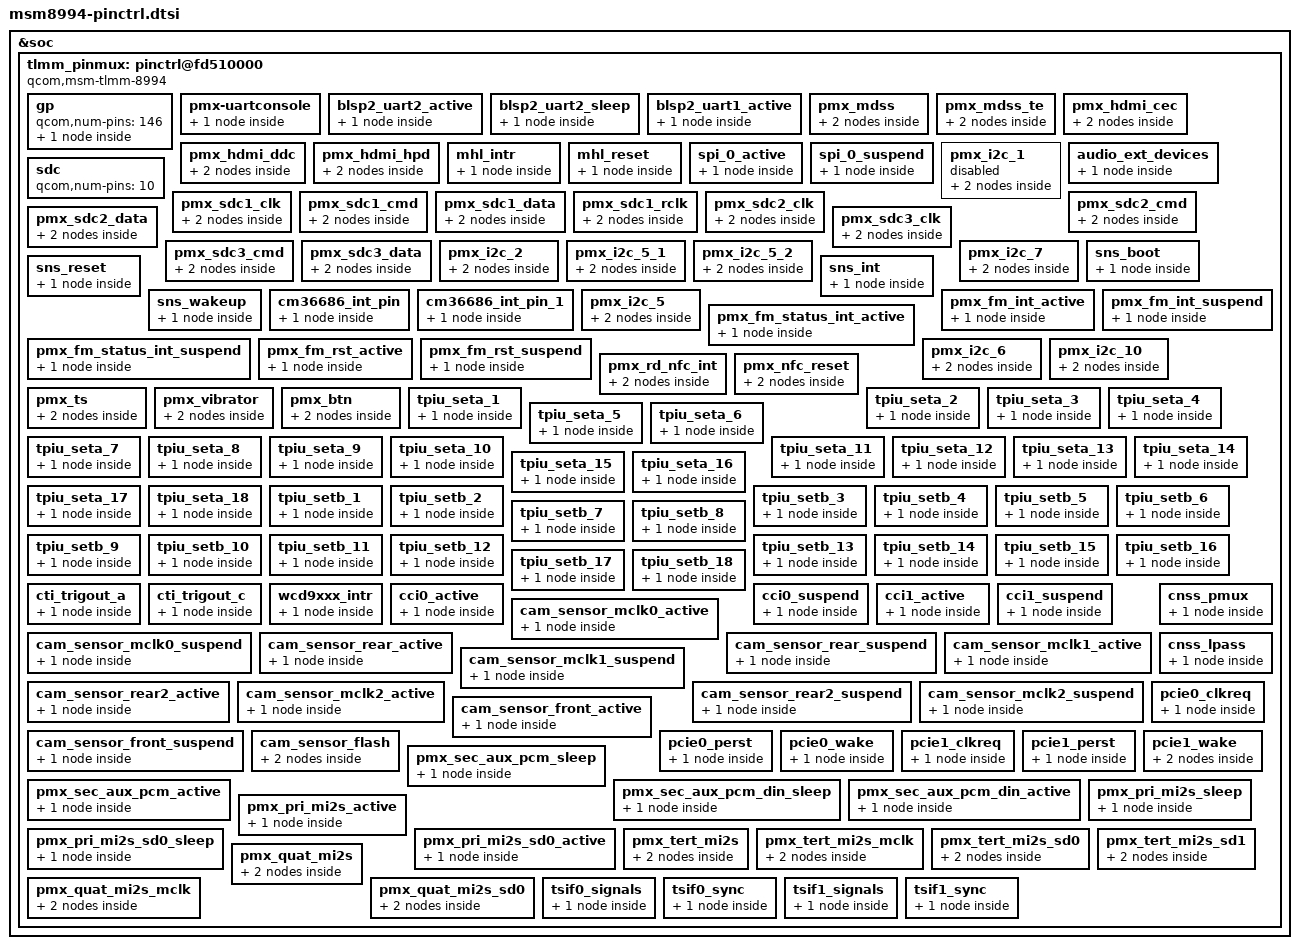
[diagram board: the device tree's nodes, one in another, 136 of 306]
/* Copyright (c) 2013-2015, The Linux Foundation. All rights reserved.
 * Copyright (C) 2016 XiaoMi, Inc.
 *
 * This program is free software; you can redistribute it and/or modify
 * it under the terms of the GNU General Public License version 2 and
 * only version 2 as published by the Free Software Foundation.
 *
 * This program is distributed in the hope that it will be useful,
 * but WITHOUT ANY WARRANTY; without even the implied warranty of
 * MERCHANTABILITY or FITNESS FOR A PARTICULAR PURPOSE.  See the
 * GNU General Public License for more details.
 */

&soc {
	tlmm_pinmux: pinctrl@fd510000 {
		compatible = "qcom,msm-tlmm-8994", "qcom,msm-tlmm-8974";
		reg = <0xfd510000 0x4000>;
		interrupts = <0 208 0>;

		/*General purpose pins*/
		gp: gp {
			qcom,num-pins = <146>;
			#qcom,pin-cells = <1>;

			msm_gpio: msm_gpio {
				compatible = "qcom,msm-tlmm-gp";
				gpio-controller;
				#gpio-cells = <2>;
				interrupt-controller;
				#interrupt-cells = <2>;
				qcom,direct-connect-irqs = <8>;
				num_irqs = <146>;
			};
		};

		pmx-uartconsole {
			qcom,pins = <&gp 4>, <&gp 5>;
			qcom,num-grp-pins = <2>;
			qcom,pin-func = <2>;
			label = "uart-console";

		uart_console_sleep: uart-console {
				drive-strength = <2>;
				bias-pull-down;
			};
		};

		blsp2_uart2_active {
			qcom,pins = <&gp 45>, <&gp 46>, <&gp 47>, <&gp 48>;
			qcom,num-grp-pins = <4>;
			qcom,pin-func = <2>;
		        label = "blsp2_uart2_active";
			hsuart_active: default {
				drive-strength = <16>;
				bias-disable;
			};
		};

		blsp2_uart2_sleep {
			qcom,pins = <&gp 45>, <&gp 46>, <&gp 47>, <&gp 48>;
			qcom,num-grp-pins = <4>;
			qcom,pin-func = <0>;
		        label = "blsp2_uart2_sleep";
			hsuart_sleep: sleep {
				drive-strength = <2>;
				bias-disable;
			};
		};
		blsp2_uart1_active {
			qcom,pins = <&gp 41>, <&gp 42>;
			qcom,num-grp-pins = <2>;
			qcom,pin-func = <2>;
			label = "blsp2_uart1_active";
			uart1_default: uart1_default {
			drive-strength = <2>;
				bias-disable;
			};
		};

		pmx_mdss: pmx_mdss {
			label = "mdss-pins";
			qcom,pin-func = <0>;
			mdss_dsi_active: active {
				drive-strength = <8>; /* 8 mA */
				bias-disable = <0>; /* no pull */
			};
			mdss_dsi_suspend: suspend {
				drive-strength = <2>; /* 2 mA */
				bias-pull-down; /* pull down */
			};
		};

		pmx_mdss_te: pmx_mdss_te {
			label = "mdss-te-pins";
			qcom,pin-func = <1>;
			mdss_te_active: active {
				drive-strength = <2>; /* 8 mA */
				bias-pull-down = <0>; /* pull down*/
				input-debounce = <0>;
			};
			mdss_te_suspend: suspend {
				drive-strength = <2>; /* 2 mA */
				bias-pull-down; /* pull down */
				input-debounce = <0>;
			};
		};

		pmx_hdmi_cec: pmx_hdmi_cec {
			qcom,pin-func = <1>;
			label = "hdmi-cec-pins";
			mdss_hdmi_cec_active: cec_active {
				drive-strength = <2>;
				bias-pull-up;
			};
			mdss_hdmi_cec_suspend: cec_suspend {
				drive-strength = <2>;
				bias-pull-down;
			};
		};

		pmx_hdmi_ddc: pmx_hdmi_ddc {
			qcom,pin-func = <1>;
			label = "hdmi-ddc-pins";
			mdss_hdmi_ddc_active: ddc_active {
				drive-strength = <2>;
				bias-pull-up;
			};
			mdss_hdmi_ddc_suspend: ddc_suspend {
				drive-strength = <2>;
				bias-pull-down;
			};
		};

		pmx_hdmi_hpd: pmx_hdmi_hpd {
			qcom,pin-func = <1>;
			label = "hdmi-hpd-pin";
			mdss_hdmi_hpd_active: hpd_active {
				drive-strength = <16>;
				bias-pull-down;
			};
			mdss_hdmi_hpd_suspend: hpd_suspend {
				drive-strength = <2>;
				bias-pull-down;
			};
		};

		mhl_intr: mhl_intr {
			qcom,pins = <&gp 57>;
			qcom,num-grp-pins = <1>;
			qcom,pin-func = <0>;
			label = "mhl_intr";

			mhl_intr_active: mhl_intr_active {
				bias-pull-up;
				input-enable;
			};
		};

		mhl_reset: mhl_reset {
			qcom,pins = <&gp 58>;
			qcom,num-grp-pins = <1>;
			qcom,pin-func = <0>;
			label = "mhl_reset";

			mhl_reset_active: mhl_reset_active {
				drive-strength = <2>;
				bias-pull-down;
				output-low;
			};
		};

		spi_0_active {
			/* MOSI, MISO, CLK */
			qcom,pins = <&gp 0>, <&gp 1>, <&gp 3>;
			qcom,num-grp-pins = <3>;
			qcom,pin-func = <1>;
			label = "spi_0-active";

			spi_0_active: spi_active {
			       drive-strength = <12>;
			       bias-disable = <0>;
		        };
		};

		spi_0_suspend {
			/* MOSI, MISO, CLK */
			qcom,pins = <&gp 0>, <&gp 1>, <&gp 3>;
			qcom,num-grp-pins = <3>;
			qcom,pin-func = <1>;
			label = "spi_0-suspend";

			spi_0_sleep: spi_sleep {
			       drive-strength = <2>;
			       bias-pull-down;
		        };
		};

		pmx_i2c_1 {
			qcom,pins = <&gp 2>, <&gp 3>; /* SDA, SCL */
			qcom,num-grp-pins = <2>;
			qcom,pin-func = <3>;
			label = "pmx_i2c_1";

			status = "disabled";

			i2c_1_active: i2c_1_active {
				drive-strength = <2>;
				bias-disable;
			};

			i2c_1_sleep: i2c_1_sleep {
				drive-strength = <2>;
				bias-disable;
			};
		};

		audio_ext_devices {
			qcom,pins = <&gp 96>;
			qcom,num-grp-pins = <1>;
			label = "audio-ext-speakers";
			/* default state */
			audio_ext_speakers: audio_ext_speakers {
				drive-strength = <2>;
				bias-pull-up;
			};
		};

		/* SDC pin type */
		sdc: sdc {
			/*
			 * 0-3 for sdc1
			 * 4-6 for sdc2
			 * 7-9 for sdc3
			 */
			qcom,num-pins = <10>;
			/*
			 * Order of pins:
			 * SDC1: CLK -> 0, CMD -> 1, DATA -> 2, RCLK -> 3
			 * SDC2: CLK -> 4, CMD -> 5, DATA -> 6
			 * SDC3: CLK -> 7, CMD -> 8, DATA -> 9
			 */
			#qcom,pin-cells = <1>;
		};

		pmx_sdc1_clk {
			qcom,pins = <&sdc 0>;
			qcom,num-grp-pins = <1>;
			label = "sdc1-clk";
			sdc1_clk_on: clk_on {
				bias-disable; /* NO pull */
				drive-strength = <16>; /* 16 MA */
			};
			sdc1_clk_off: clk_off {
				bias-disable; /* NO pull */
				drive-strength = <2>; /* 2 MA */
			};
		};

		pmx_sdc1_cmd {
			qcom,pins = <&sdc 1>;
			qcom,num-grp-pins = <1>;
			label = "sdc1-cmd";
			sdc1_cmd_on: cmd_on {
				bias-pull-up; /* pull up */
				drive-strength = <8>; /* 8 MA */
			};
			sdc1_cmd_off: cmd_off {
				bias-pull-up = <0x3>; /* pull up */
				drive-strength = <2>; /* 2 MA */
			};
		};

		pmx_sdc1_data {
			qcom,pins = <&sdc 2>;
			qcom,num-grp-pins = <1>;
			label = "sdc1-data";
			sdc1_data_on: data_on {
				bias-pull-up; /* pull up */
				drive-strength = <8>; /* 8 MA */
			};
			sdc1_data_off: data_off {
				bias-pull-up; /* pull up */
				drive-strength = <2>; /* 2 MA */
			};
		};

		pmx_sdc1_rclk {
			qcom,pins = <&sdc 3>;
			qcom,num-grp-pins = <1>;
			label = "sdc1-rclk";
			sdc1_rclk_on: rclk_on {
				bias-pull-down; /* pull down */
			};
			sdc1_rclk_off: rclk_off {
				bias-pull-down; /* pull down */
			};
		};

		pmx_sdc2_clk {
			qcom,pins = <&sdc 4>;
			qcom,num-grp-pins = <1>;
			label = "sdc2-clk";
			sdc2_clk_on: clk_on {
				bias-disable; /* NO pull */
				drive-strength = <16>; /* 16 MA */
			};
			sdc2_clk_off: clk_off {
				bias-disable; /* NO pull */
				drive-strength = <2>; /* 2 MA */
			};
		};

		pmx_sdc2_cmd {
			qcom,pins = <&sdc 5>;
			qcom,num-grp-pins = <1>;
			label = "sdc2-cmd";
			sdc2_cmd_on: cmd_on {
				bias-pull-up; /* pull up */
				drive-strength = <10>; /* 10 MA */
			};
			sdc2_cmd_off: cmd_off {
				bias-pull-up; /* pull up */
				drive-strength = <2>; /* 2 MA */
			};
		};

		pmx_sdc2_data {
			qcom,pins = <&sdc 6>;
			qcom,num-grp-pins = <1>;
			label = "sdc2-data";
			sdc2_data_on: data_on {
				bias-pull-up; /* pull up */
				drive-strength = <10>; /* 10 MA */
			};
			sdc2_data_off: data_off {
				bias-pull-up; /* pull up */
				drive-strength = <2>; /* 2 MA */
			};
		};

		pmx_sdc3_clk {
			qcom,pins = <&sdc 7>;
			qcom,num-grp-pins = <1>;
			label = "sdc3-clk";
			sdc3_clk_on: clk_on {
				bias-disable; /* NO pull */
				drive-strength = <16>; /* 16 MA */
			};
			sdc3_clk_off: clk_off {
				bias-disable; /* NO pull */
				drive-strength = <2>; /* 2 MA */
			};
		};

		pmx_sdc3_cmd {
			qcom,pins = <&sdc 8>;
			qcom,num-grp-pins = <1>;
			label = "sdc3-cmd";
			sdc3_cmd_on: cmd_on {
				bias-pull-up; /* pull up */
				drive-strength = <10>; /* 10 MA */
			};
			sdc3_cmd_off: cmd_off {
				bias-pull-up; /* pull up */
				drive-strength = <2>; /* 2 MA */
			};
		};

		pmx_sdc3_data {
			qcom,pins = <&sdc 9>;
			qcom,num-grp-pins = <1>;
			label = "sdc3-data";
			sdc3_data_on: data_on {
				bias-pull-up; /* pull up */
				drive-strength = <10>; /* 10 MA */
			};
			sdc3_data_off: data_off {
				bias-pull-up; /* pull up */
				drive-strength = <2>; /* 2 MA */
			};
		};

		pmx_i2c_2 {
			qcom,pins = <&gp 6>, <&gp 7>; /* SDA, SCL */
			qcom,num-grp-pins = <2>;
			qcom,pin-func = <3>;
			label = "pmx_i2c_2";

			i2c_2_active: i2c_2_active {
				drive-strength = <2>;
				bias-disable;
			};

			i2c_2_sleep: i2c_2_sleep {
				drive-strength = <2>;
				bias-disable;
			};
		};

		pmx_i2c_5_1 {
			qcom,pins = <&gp 23>; /* SDA*/
			qcom,num-grp-pins = <1>;
			qcom,pin-func = <4>;
			label = "pmx_i2c_5_1";

			i2c_5_1_active: i2c_5_1_active {
				drive-strength = <2>;
				bias-disable;
			};

			i2c_5_1_sleep: i2c_5_1_sleep {
				drive-strength = <2>;
				bias-disable;
			};
		};

		pmx_i2c_5_2 {
			qcom,pins = <&gp 24>; /* SCL*/
			qcom,num-grp-pins = <1>;
			qcom,pin-func = <5>;
			label = "pmx_i2c_5_2";

			i2c_5_2_active: i2c_5_2_active {
				drive-strength = <2>;
				bias-disable;
			};

			i2c_5_2_sleep: i2c_5_2_sleep {
				drive-strength = <2>;
				bias-disable;
			};
		};

		pmx_i2c_7 {
			qcom,pins = <&gp 43>, <&gp 44>; /* SDA, SCL */
			qcom,num-grp-pins = <2>;
			qcom,pin-func = <3>;
			label = "pmx_i2c_7";

			i2c_7_active: i2c_7_active {
			drive-strength = <2>;
			bias-disable;
			};

			i2c_7_sleep: i2c_7_sleep {
				drive-strength = <2>;
				bias-disable;
			};
		};

		sns_boot: sns_boot {
			qcom,pins = <&gp 40>;
			qcom,num-grp-pins = <1>;
			qcom,pin-func = <0>;
			label = "sns_boot";

			sns_boot_default: sns_boot_default {
				bias-disable;
				output-high;
				drive-strength = <2>;
			};

		};

		sns_reset: sns_reset {
			qcom,pins = <&gp 31>;
			qcom,num-grp-pins = <1>;
			qcom,pin-func = <0>;
			label = "sns_reset";

			sns_reset_default: sns_reset_default {
				bias-disable;
				output-high;
				drive-strength = <2>;
			};
		};

		sns_int: sns_int {
			qcom,pins = <&gp 1>;
			qcom,num-grp-pins = <1>;
			qcom,pin-func = <0>;
			label = "sns_int";

			sns_int_default: sns_int_default {
				bias-pull-up;
				input-enable;
				drive-strength = <2>;
			};
		};

		sns_wakeup: sns_wakeup {
			qcom,pins = <&gp 39>;
			qcom,num-grp-pins = <1>;
			qcom,pin-func = <0>;
			label = "sns_wakeup";

			sns_wakeup_default: sns_wakeup_default {
				bias-disable;
				output-low;
				drive-strength = <2>;
			};
		};

		cm36686_int_pin {
			qcom,pins = <&gp 90>;
			qcom,num-grp-pins = <1>;
			qcom,pin-func = <0>;
			label = "cm36686-irq";
			cm36686_int_default: cm36686_int_default {
				bias-pull-up;
				input-enable;
				drive-strength = <2>;
			};
		};

		cm36686_int_pin_1 {
			qcom,pins = <&gp 102>;
			qcom,num-grp-pins = <1>;
			qcom,pin-func = <0>;
			label = "cm36686-irq_1";
			cm36686_int_default_1: cm36686_int_default_1 {
				bias-pull-up;
				input-enable;
				drive-strength = <2>;
			};
		};


		pmx_i2c_5 {
			qcom,pins = <&gp 83>, <&gp 84>; /* SDA, SCL */
			qcom,num-grp-pins = <2>;
			qcom,pin-func = <3>;
			label = "pmx_i2c_5";

			i2c_5_active: i2c_5_active {
				drive-strength = <2>;
				bias-disable;
			};

			i2c_5_sleep: i2c_5_sleep {
				drive-strength = <2>;
				bias-disable;
			};
		};

		pmx_fm_int_active {
			qcom,pins = <&gp 9>;
			qcom,pin-func = <0>;
			qcom,num-grp-pins = <1>;
			label = "pmx_fm_int_active";

			fm_int_active: fm_int_active {
				drive-strength = <16>;
				bias-pull-up;
			};
		};

		pmx_fm_int_suspend {
			qcom,pins = <&gp 9>;
			qcom,pin-func = <0>;
			qcom,num-grp-pins = <1>;
			label = "pmx_fm_int_suspend";

			fm_int_suspend: fm_int_suspend {
				drive-strength = <16>;
				bias-pull-up;
			};
		};

		pmx_fm_status_int_active {
			qcom,pins = <&gp 11>;
			qcom,pin-func = <0>;
			qcom,num-grp-pins = <1>;
			label = "pmx_fm_status_int_active";

			fm_status_int_active: fm_status_int_active {
				drive-strength = <16>;
				bias-pull-up;
			};
		};

		pmx_fm_status_int_suspend {
			qcom,pins = <&gp 11>;
			qcom,pin-func = <0>;
			qcom,num-grp-pins = <1>;
			label = "pmx_fm_status_int_suspend";

			fm_status_int_suspend: fm_status_int_suspend {
				drive-strength = <16>;
				bias-pull-up;
			};
		};

		pmx_fm_rst_active {
			qcom,pins = <&gp 62>;
			qcom,pin-func = <0>;
			qcom,num-grp-pins = <1>;
			label = "pmx_fm_rst_active";

			fm_rst_active: fm_rst_active {
				drive-strength = <16>;
				bias-pull-down;
			};
		};

		pmx_fm_rst_suspend {
			qcom,pins = <&gp 62>;
			qcom,pin-func = <0>;
			qcom,num-grp-pins = <1>;
			label = "pmx_fm_rst_suspend";

			fm_rst_suspend: fm_rst_suspend {
				drive-strength = <16>;
				bias-pull-down;
			};
		};

		pmx_i2c_6 {
			qcom,pins = <&gp 28>, <&gp 27>; /* SDA, SCL */
			qcom,num-grp-pins = <2>;
			qcom,pin-func = <3>;
			label = "pmx_i2c_6";

			i2c_6_active: i2c_6_active {
				drive-strength = <2>;
				bias-disable;
			};

			i2c_6_sleep: i2c_6_sleep {
				drive-strength = <2>;
				bias-disable;
			};
		};

		pmx_i2c_10 {
			qcom,pins = <&gp 55>, <&gp 56>; /* SDA, SCL */
			qcom,num-grp-pins = <2>;
			qcom,pin-func = <4>;
			label = "pmx_i2c_10";

			i2c_10_active: i2c_10_active {
				drive-strength = <2>;
				bias-disable;
			};

			i2c_10_sleep: i2c_10_sleep {
				drive-strength = <2>;
				bias-disable;
			};
		};

		pmx_rd_nfc_int{
			qcom,pins = <&gp 29>;
			qcom,pin-func = <0>;
			qcom,num-grp-pins = <1>;
			label = "pmx_nfc_int";

			nfc_int_active: active {
				drive-strength = <6>;
				bias-pull-up;
			};

			nfc_int_suspend: suspend {
				drive-strength = <6>;
				bias-pull-up;
			};
		};

		pmx_nfc_reset{
			qcom,pins = <&gp 30>;
			qcom,pin-func = <0>;
			qcom,num-grp-pins = <1>;
			label = "pmx_nfc_disable";

			nfc_disable_active: active {
				drive-strength = <6>;
				bias-pull-up;
			};

			nfc_disable_suspend: suspend {
				drive-strength = <6>;
				bias-disable;
			};
		};

		pmx_ts {
			qcom,pins = <&gp 63>, <&gp 61>;
			qcom,pin-func = <0>;
			qcom,num-grp-pins = <2>;
			label = "pmx_ts";

			ts_active: ts_active {
				drive-strength = <8>;
				bias-pull-up;
			};

			ts_suspend: ts_suspend {
				drive-strength = <8>;
				bias-disable;
			};
		};

		pmx_vibrator {
			qcom,pins = <&gp 21>;
			qcom,pin-func = <0>;
			qcom,num-grp-pins = <1>;
			label = "pmx_vibrator";

			vibrator_active: vibrator_active {
				drive-strength = <8>;
				bias-pull-up;
			};

			vibrator_suspend: vibrator_suspend {
				drive-strength = <8>;
				bias-disable;
			};
		};

		pmx_btn {
			qcom,pins = <&gp 114>;
			qcom,pin-func = <0>;
			qcom,num-grp-pins = <1>;
			label = "pmx_btn";

			btn_active: btn_active {
				drive-strength = <8>;
				bias-pull-up;
			};

			btn_suspend: btn_suspend {
				drive-strength = <8>;
				bias-disable;
			};
		};

		/* CoreSight */
		tpiu_seta_1 {
			qcom,pins = <&gp 27>;
			qcom,num-grp-pins = <1>;
			qcom,pin-func = <5>;
			label = "tpiu-seta-1";
			seta_1: seta {
				drive-strength = <16>;
				bias-disable;
			};
		};

		tpiu_seta_2 {
			qcom,pins = <&gp 28>;
			qcom,num-grp-pins = <1>;
			qcom,pin-func = <4>;
			label = "tpiu-seta-2";
			seta_2: seta {
				drive-strength = <16>;
				bias-disable;
			};
		};

		tpiu_seta_3 {
			qcom,pins = <&gp 53>;
			qcom,num-grp-pins = <1>;
			qcom,pin-func = <10>;
			label = "tpiu-seta-3";
			seta_3: seta {
				drive-strength = <16>;
				bias-disable;
			};
		};

		tpiu_seta_4 {
			qcom,pins = <&gp 54>;
			qcom,num-grp-pins = <1>;
			qcom,pin-func = <11>;
			label = "tpiu-seta-4";
			seta_4: seta {
				drive-strength = <16>;
				bias-disable;
			};
		};

		tpiu_seta_5 {
			//qcom,pins = <&gp 63>;
			qcom,num-grp-pins = <1>;
			qcom,pin-func = <9>;
			label = "tpiu-seta-5";
			seta_5: seta {
				drive-strength = <16>;
				bias-disable;
			};
		};

		tpiu_seta_6 {
			qcom,pins = <&gp 64>;
			qcom,num-grp-pins = <1>;
			qcom,pin-func = <7>;
			label = "tpiu-seta-6";
			seta_6: seta {
				drive-strength = <16>;
				bias-disable;
			};
		};

		tpiu_seta_7 {
			qcom,pins = <&gp 65>;
			qcom,num-grp-pins = <1>;
			qcom,pin-func = <7>;
			label = "tpiu-seta-7";
			seta_7: seta {
				drive-strength = <16>;
				bias-disable;
			};
		};

		tpiu_seta_8 {
			qcom,pins = <&gp 66>;
			qcom,num-grp-pins = <1>;
			qcom,pin-func = <8>;
			label = "tpiu-seta-8";
			seta_8: seta {
				drive-strength = <16>;
				bias-disable;
			};
		};

		tpiu_seta_9 {
			qcom,pins = <&gp 67>;
			qcom,num-grp-pins = <1>;
			qcom,pin-func = <8>;
			label = "tpiu-seta-9";
			seta_9: seta {
				drive-strength = <16>;
				bias-disable;
			};
		};

		tpiu_seta_10 {
			qcom,pins = <&gp 74>;
			qcom,num-grp-pins = <1>;
			qcom,pin-func = <8>;
			label = "tpiu-seta-10";
			seta_10: seta {
				drive-strength = <16>;
				bias-disable;
			};
		};

		tpiu_seta_11 {
			qcom,pins = <&gp 75>;
			qcom,num-grp-pins = <1>;
			qcom,pin-func = <6>;
			label = "tpiu-seta-11";
			seta_11: seta {
				drive-strength = <16>;
				bias-disable;
			};
		};

		tpiu_seta_12 {
			qcom,pins = <&gp 76>;
			qcom,num-grp-pins = <1>;
			qcom,pin-func = <6>;
			label = "tpiu-seta-12";
			seta_12: seta {
				drive-strength = <16>;
				bias-disable;
			};
		};

		tpiu_seta_13 {
			qcom,pins = <&gp 77>;
			qcom,num-grp-pins = <1>;
			qcom,pin-func = <6>;
			label = "tpiu-seta-13";
			seta_13: seta {
				drive-strength = <16>;
				bias-disable;
			};
		};

		tpiu_seta_14 {
			qcom,pins = <&gp 85>;
			qcom,num-grp-pins = <1>;
			qcom,pin-func = <6>;
			label = "tpiu-seta-14";
			seta_14: seta {
				drive-strength = <16>;
				bias-disable;
			};
		};

		tpiu_seta_15 {
			qcom,pins = <&gp 86>;
			qcom,num-grp-pins = <1>;
			qcom,pin-func = <6>;
			label = "tpiu-seta-15";
			seta_15: seta {
				drive-strength = <16>;
				bias-disable;
			};
		};

		tpiu_seta_16 {
			qcom,pins = <&gp 87>;
			qcom,num-grp-pins = <1>;
			qcom,pin-func = <5>;
			label = "tpiu-seta-16";
			seta_16: seta {
				drive-strength = <16>;
				bias-disable;
			};
		};

		tpiu_seta_17 {
			qcom,pins = <&gp 89>;
			qcom,num-grp-pins = <1>;
			qcom,pin-func = <3>;
			label = "tpiu-seta-17";
			seta_17: seta {
				drive-strength = <16>;
				bias-disable;
			};
		};

		tpiu_seta_18 {
			qcom,pins = <&gp 90>;
			qcom,num-grp-pins = <1>;
			qcom,pin-func = <3>;
			label = "tpiu-seta-18";
			seta_18: seta {
				drive-strength = <16>;
				bias-disable;
			};
		};

		tpiu_setb_1 {
			qcom,pins = <&gp 13>;
			qcom,num-grp-pins = <1>;
			qcom,pin-func = <4>;
			label = "tpiu-setb-1";
			setb_1: setb {
				drive-strength = <16>;
				bias-disable;
			};
		};

		tpiu_setb_2 {
			qcom,pins = <&gp 14>;
			qcom,num-grp-pins = <1>;
			qcom,pin-func = <4>;
			label = "tpiu-setb-2";
			setb_2: setb {
				drive-strength = <16>;
				bias-disable;
			};
		};

		tpiu_setb_3 {
			qcom,pins = <&gp 15>;
			qcom,num-grp-pins = <1>;
			qcom,pin-func = <3>;
			label = "tpiu-setb-3";
			setb_3: setb {
				drive-strength = <16>;
				bias-disable;
			};
		};

		tpiu_setb_4 {
			qcom,pins = <&gp 16>;
			qcom,num-grp-pins = <1>;
			qcom,pin-func = <3>;
			label = "tpiu-setb-4";
			setb_4: setb {
				drive-strength = <16>;
				bias-disable;
			};
		};

		tpiu_setb_5 {
			qcom,pins = <&gp 17>;
			qcom,num-grp-pins = <1>;
			qcom,pin-func = <6>;
			label = "tpiu-setb-5";
			setb_5: setb {
				drive-strength = <16>;
				bias-disable;
			};
		};

		tpiu_setb_6 {
			qcom,pins = <&gp 18>;
			qcom,num-grp-pins = <1>;
			qcom,pin-func = <6>;
			label = "tpiu-setb-6";
			setb_6: setb {
				drive-strength = <16>;
				bias-disable;
			};
		};

		tpiu_setb_7 {
			qcom,pins = <&gp 19>;
			qcom,num-grp-pins = <1>;
			qcom,pin-func = <6>;
			label = "tpiu-setb-7";
			setb_7: setb {
				drive-strength = <16>;
				bias-disable;
			};
		};

		tpiu_setb_8 {
			qcom,pins = <&gp 21>;
			qcom,num-grp-pins = <1>;
			qcom,pin-func = <6>;
			label = "tpiu-setb-8";
			setb_8: setb {
				drive-strength = <16>;
				bias-disable;
			};
		};

		tpiu_setb_9 {
			qcom,pins = <&gp 22>;
			qcom,num-grp-pins = <1>;
			qcom,pin-func = <6>;
			label = "tpiu-setb-9";
			setb_9: setb {
				drive-strength = <16>;
				bias-disable;
			};
		};

		tpiu_setb_10 {
			qcom,pins = <&gp 23>;
			qcom,num-grp-pins = <1>;
			qcom,pin-func = <7>;
			label = "tpiu-setb-10";
			setb_10: setb {
				drive-strength = <16>;
				bias-disable;
			};
		};

		tpiu_setb_11 {
			qcom,pins = <&gp 25>;
			qcom,num-grp-pins = <1>;
			qcom,pin-func = <8>;
			label = "tpiu-setb-11";
			setb_11: setb {
				drive-strength = <16>;
				bias-disable;
			};
		};

		tpiu_setb_12 {
			qcom,pins = <&gp 26>;
			qcom,num-grp-pins = <1>;
			qcom,pin-func = <7>;
			label = "tpiu-setb-12";
			setb_12: setb {
				drive-strength = <16>;
				bias-disable;
			};
		};

		tpiu_setb_13 {
			qcom,pins = <&gp 57>;
			qcom,num-grp-pins = <1>;
			qcom,pin-func = <7>;
			label = "tpiu-setb-13";
			setb_13: setb {
				drive-strength = <16>;
				bias-disable;
			};
		};

		tpiu_setb_14 {
			qcom,pins = <&gp 58>;
			qcom,num-grp-pins = <1>;
			qcom,pin-func = <7>;
			label = "tpiu-setb-14";
			setb_14: setb {
				drive-strength = <16>;
				bias-disable;
			};
		};

		tpiu_setb_15 {
			qcom,pins = <&gp 91>;
			qcom,num-grp-pins = <1>;
			qcom,pin-func = <7>;
			label = "tpiu-setb-15";
			setb_15: setb {
				drive-strength = <16>;
				bias-disable;
			};
		};

		tpiu_setb_16 {
			qcom,pins = <&gp 92>;
			qcom,num-grp-pins = <1>;
			qcom,pin-func = <5>;
			label = "tpiu-setb-16";
			setb_16: setb {
				drive-strength = <16>;
				bias-disable;
			};
		};

		tpiu_setb_17 {
			qcom,pins = <&gp 93>;
			qcom,num-grp-pins = <1>;
			qcom,pin-func = <7>;
			label = "tpiu-setb-17";
			setb_17: setb {
				drive-strength = <16>;
				bias-disable;
			};
		};

		tpiu_setb_18 {
			qcom,pins = <&gp 94>;
			qcom,num-grp-pins = <1>;
			qcom,pin-func = <7>;
			label = "tpiu-setb-18";
			setb_18: setb {
				drive-strength = <16>;
				bias-disable;
			};
		};

		cti_trigout_a {
			qcom,pins = <&gp 56>;
			qcom,num-grp-pins = <1>;
			qcom,pin-func = <9>;
			label = "cti-trigout-a";
			trigout_a: trigout_a {
				drive-strength = <2>;
				bias-disable;
			};
		};

		cti_trigout_c {
			qcom,pins = <&gp 41>;
			qcom,num-grp-pins = <1>;
			qcom,pin-func = <4>;
			label = "cti-trigout-c";
			trigout_c: trigout_c {
				drive-strength = <2>;
				bias-disable;
			};
		};

		wcd9xxx_intr {
			qcom,pins = <&gp 72>;
			qcom,num-grp-pins = <1>;
			qcom,pin-func = <0>;
			label = "wcd-intr-default";
			wcd_intr_default: default {
				drive-strength = <2>; /* 2 MA */
				bias-pull-down; /* pull down */
				input-enable;
			};
		};

		cci0_active {
			/* CLK, DATA */
			qcom,pins = <&gp 17>, <&gp 18>;
			qcom,num-grp-pins = <2>;
			qcom,pin-func = <1>;
			label = "cci0-active";
			/* active state */
			cci0_active: cci0_active {
				drive-strength = <2>; /* 2 MA */
				bias-disable; /* No PULL */
			};
		};

		cci0_suspend {
			/* CLK, DATA */
			qcom,pins = <&gp 17>, <&gp 18>;
			qcom,num-grp-pins = <2>;
			qcom,pin-func = <0>;
			label = "cci0-suspend";
			/*suspended state */
			cci0_suspend: cci0_suspend {
				drive-strength = <2>; /* 2 MA */
				bias-disable; /* No PULL */
			};
		};

		cci1_active {
			/* CLK, DATA */
			qcom,pins = <&gp 19>, <&gp 20>;
			qcom,num-grp-pins = <2>;
			qcom,pin-func = <1>;
			label = "cci1-active";
			/* active state */
			cci1_active: cci1_active {
				drive-strength = <2>; /* 2 MA */
				bias-disable; /* No PULL */
			};
		};

		cci1_suspend {
			/* CLK, DATA */
			qcom,pins = <&gp 19>, <&gp 20>;
			qcom,num-grp-pins = <2>;
			qcom,pin-func = <0>;
			label = "cci1-suspend";
			/*suspended state */
			cci1_suspend: cci1_suspend {
				drive-strength = <2>; /* 2 MA */
				bias-disable; /* No PULL */
			};
		};

		cam_sensor_mclk0_active {
			/* MCLK0 */
			qcom,pins = <&gp 13>;
			qcom,num-grp-pins = <1>;
			qcom,pin-func = <1>;
			label = "cam_sensor_mclk0_active";
			/* active state */
			cam_sensor_mclk0_active: cam_sensor_mclk0_active {
				drive-strength = <2>; /* 2 MA */
				bias-disable; /* No PULL */
			};
		};

		cam_sensor_mclk0_suspend {
			/* MCLK0 */
			qcom,pins = <&gp 13>;
			qcom,num-grp-pins = <1>;
			label = "cam_sensor_mclk0_suspend";
			/*suspended state */
			cam_sensor_mclk0_suspend: cam_sensor_mclk0_suspend {
				drive-strength = <2>; /* 2 MA */
				bias-pull-down; /* PULL DOWN */
			};
		};

		cam_sensor_rear_active {
			/* RESET, STANDBY */
			qcom,pins = <&gp 16>, <&gp 91>;
			qcom,num-grp-pins = <2>;
			label = "cam_sensor_rear_active";
			/* active state */
			cam_sensor_rear_active: cam_sensor_rear_active {
				drive-strength = <2>; /* 2 MA */
				bias-disable; /* No PULL */
			};
		};

		cam_sensor_rear_suspend {
			/* RESET, STANDBY */
			qcom,pins = <&gp 16>, <&gp 91>;
			qcom,num-grp-pins = <2>;
			label = "cam_sensor_rear_suspend";
			/*suspended state */
			cam_sensor_rear_suspend: cam_sensor_rear_suspend {
				drive-strength = <2>; /* 2 MA */
				bias-disable; /* No PULL */
			};
		};

		cam_sensor_mclk1_active {
			/* MCLK2 */
			qcom,pins = <&gp 14>;
			qcom,num-grp-pins = <1>;
			qcom,pin-func = <1>;
			label = "cam_sensor_mclk1_active";
			/* active state */
			cam_sensor_mclk1_active: cam_sensor_mclk1_active {
				drive-strength = <2>; /* 2 MA */
				bias-disable; /* No PULL */
			};
		};

		cam_sensor_mclk1_suspend {
			/* MCLK2 */
			qcom,pins = <&gp 14>;
			qcom,num-grp-pins = <1>;
			label = "cam_sensor_mclk1_suspend";
			/* suspend state */
			cam_sensor_mclk1_suspend: cam_sensor_mclk1_suspend {
				drive-strength = <2>; /* 2 MA */
				bias-pull-down; /* PULL DOWN */
			};
		};

		cam_sensor_rear2_active {
			/* RESET, STANDBY */
			qcom,pins = <&gp 94>, <&gp 93>;
			qcom,num-grp-pins = <2>;
			label = "cam_sensor_rear2_active";
			/* active state */
			cam_sensor_rear2_active: cam_sensor_rear2_active {
				drive-strength = <2>; /* 2 MA */
				bias-disable; /* No PULL */
			};
		};

		cam_sensor_rear2_suspend {
			/* RESET, STANDBY */
			qcom,pins = <&gp 94>, <&gp 93>;
			qcom,num-grp-pins = <2>;
			label = "cam_sensor_rear2_suspend";
			/*suspended state */
			cam_sensor_rear2_suspend: cam_sensor_rear2_suspend {
				drive-strength = <2>; /* 2 MA */
				bias-disable; /* No PULL */
			};
		};

		cam_sensor_mclk2_active {
			/* MCLK2 */
			qcom,pins = <&gp 15>;
			qcom,num-grp-pins = <1>;
			qcom,pin-func = <1>;
			label = "cam_sensor_mclk2_active";
			/* active state */
			cam_sensor_mclk2_active: cam_sensor_mclk2_active {
				drive-strength = <2>; /* 2 MA */
				bias-disable; /* No PULL */
			};
		};

		cam_sensor_mclk2_suspend {
			/* MCLK2 */
			qcom,pins = <&gp 15>;
			qcom,num-grp-pins = <1>;
			label = "cam_sensor_mclk2_suspend";
			/* suspend state */
			cam_sensor_mclk2_suspend: cam_sensor_mclk2_suspend {
				drive-strength = <2>; /* 2 MA */
				bias-pull-down; /* PULL DOWN */
			};
		};

		cam_sensor_front_active {
			/* RESET, STANDBY */
			qcom,pins = <&gp 104>, <&gp 105>;
			qcom,num-grp-pins = <2>;
			label = "cam_sensor_front_active";
			/* active state */
			cam_sensor_front_active: cam_sensor_front_active {
				drive-strength = <2>; /* 2 MA */
				bias-disable; /* No PULL */
			};
		};

		cam_sensor_front_suspend {
			/* RESET, STANDBY */
			qcom,pins = <&gp 104>, <&gp 105>;
			qcom,num-grp-pins = <2>;
			label = "cam_sensor_front_suspend";
			/*suspended state */
			cam_sensor_front_suspend: cam_sensor_front_suspend {
				drive-strength = <2>; /* 2 MA */
				bias-disable; /* No PULL */
			};
		};

		cam_sensor_flash {
			qcom,pins = <&gp 22>,<&gp 29>,<&gp 30>;
			qcom,num-grp-pins = <3>;
			qcom,pin-func = <0>;
			label = "cam_sensor_flash";

			cam_sensor_flash_default: default {
			drive-strength = <2>; /* 2 MA */
				bias-disable = <0>; /* No PULL */
			};

			cam_sensor_flash_sleep: sleep {
				drive-strength = <2>; /* 2 MA */
				bias-pull-down = <0>; /* PULL DOWN */
			};
		};

		cnss_pmux: cnss_pmux {
			qcom,pins = <&gp 113>;
			qcom,num-grp-pins = <1>;
			qcom,pin-func = <0>;
			label = "cnss_pins";
			cnss_default: default {
				drive-strength = <16>;
				bias-pull-down;
			};
		};

		cnss_lpass: cnss_lpass {
			qcom,pins = <&gp 112>;
			qcom,num-grp-pins = <1>;
			qcom,pin-func = <0>;
			label = "cnss-lpass";
			/* default state */
			cnss_lpass_default: cnss_lpass_default {
				drive-strength = <16>;
				bias-pull-down;
			};
		};

		pcie0_clkreq {
			qcom,pins = <&gp 54>;
			qcom,num-grp-pins = <1>;
			qcom,pin-func = <2>;
			label = "pcie0-clkreq";
			/* default state */
			pcie0_clkreq_default: pcie0_clkreq_default {
				drive-strength = <2>;
				bias-pull-up;
			};
		};

		pcie0_perst {
			qcom,pins = <&gp 53>;
			qcom,num-grp-pins = <1>;
			label = "pcie0-perst";
			/* default state */
			pcie0_perst_default: pcie0_perst_default {
				drive-strength = <2>;
				bias-pull-down;
			};
		};

		pcie0_wake {
			qcom,pins = <&gp 55>;
			qcom,num-grp-pins = <1>;
			label = "pcie0-wake";
			/* default state */
			pcie0_wake_default: pcie0_wake_default {
				drive-strength = <2>;
				bias-pull-down;
			};
		};

		pcie1_clkreq {
			qcom,pins = <&gp 36>;
			qcom,num-grp-pins = <1>;
			qcom,pin-func = <2>;
			label = "pcie1-clkreq";
			/* default state */
			pcie1_clkreq_default: pcie1_clkreq_default {
				drive-strength = <2>;
				bias-pull-up;
			};
		};

		pcie1_perst {
			qcom,pins = <&gp 35>;
			qcom,num-grp-pins = <1>;
			label = "pcie1-perst";
			/* default state */
			pcie1_perst_default: pcie1_perst_default {
				drive-strength = <2>;
				bias-pull-down;
			};
		};

		pcie1_wake {
			qcom,pins = <&gp 37>;
			qcom,num-grp-pins = <1>;
			label = "pcie1-wake";
			/* default state */
			pcie1_wake_default: pcie1_wake_default {
				drive-strength = <2>;
				bias-pull-down;
			};

			pcie1_wake_sleep: pcie1_wake_sleep {
				drive-strength = <2>;
				bias-disable;
			};
		};

		pmx_sec_aux_pcm_sleep {
			qcom,pins = <&gp 79>, <&gp 80>, <&gp 82>;
			qcom,num-grp-pins = <3>;
			qcom,pin-func = <0>;
			label = "pmx_sec_aux_pcm_sleep";
			sec_aux_pcm_sleep: sec_aux_pcm_sleep {
				drive-strength = <2>;	/* 2 mA */
				bias-pull-down;		/* PULL DOWN */
				input-enable;
			};
		};

		pmx_sec_aux_pcm_active {
			qcom,pins = <&gp 79>, <&gp 80>, <&gp 82>;
			qcom,num-grp-pins = <3>;
			qcom,pin-func = <1>;
			label = "pmx_sec_aux_pcm_active";
			sec_aux_pcm_active: sec_aux_pcm_active {
				drive-strength = <8>;	/* 8 mA */
				bias-disable;		/* NO PULL */
				output-high;
			};
		};

		pmx_sec_aux_pcm_din_sleep {
			qcom,pins = <&gp 81>;
			qcom,num-grp-pins = <1>;
			qcom,pin-func = <0>;
			label = "pmx_sec_aux_pcm_din_sleep";
			sec_aux_pcm_din_sleep: sec_aux_pcm_din_sleep {
				drive-strength = <2>;	/* 2 mA */
				bias-pull-down;		/* PULL DOWN */
				input-enable;
			};
		};

		pmx_sec_aux_pcm_din_active {
			qcom,pins = <&gp 81>;
			qcom,num-grp-pins = <1>;
			qcom,pin-func = <1>;
			label = "pmx_sec_aux_pcm_din_active";
			sec_aux_pcm_din_active: sec_aux_pcm_din_active {
				drive-strength = <8>;	/* 8 mA */
				bias-disable;		/* NO PULL */
			};
		};

		pmx_pri_mi2s_sleep {
			qcom,pins = <&gp 65>, <&gp 66>;
			qcom,num-grp-pins = <2>;
			qcom,pin-func = <0>;
			label = "pri_mi2s_sleep";
			pri_mi2s_sleep: pri_mi2s_sleep {
				drive-strength = <2>;	/* 2 mA */
				bias-pull-down;		/* PULL DOWN */
				input-enable;
			};
		};

		pmx_pri_mi2s_active {
			qcom,pins = <&gp 65>, <&gp 66>;
			qcom,num-grp-pins = <2>;
			qcom,pin-func = <1>;
			label = "pri_mi2s_active";
			pri_mi2s_active: pri_mi2s_active {
				drive-strength = <2>;	/* 2 mA */
				bias-disable;		/* NO PULL */
				output-high;
			};
		};

		pmx_pri_mi2s_sd0_sleep {
			qcom,pins = <&gp 67>;
			qcom,num-grp-pins = <1>;
			qcom,pin-func = <0>;
			label = "pri_mi2s_sd0_sleep";
			pri_mi2s_sd0_sleep: pri_mi2s_sd0_sleep {
				drive-strength = <2>;	/* 2 mA */
				bias-pull-down;		/* PULL DOWN */
				input-enable;
			};
		};

		pmx_pri_mi2s_sd0_active {
			qcom,pins = <&gp 67>;
			qcom,num-grp-pins = <1>;
			qcom,pin-func = <1>;
			label = "pri_mi2s_sd0_active";
			pri_mi2s_sd0_active: pri_mi2s_sd0_active {
				drive-strength = <2>;	/* 2 mA */
				bias-disable;		/* NO PULL */
			};
		};

                pmx_tert_mi2s {
			qcom,pins = <&gp 74>, <&gp 75>;
			qcom,num-grp-pins = <2>;
			qcom,pin-func = <1>;
			label = "tert_mi2s";
			tert_mi2s_sleep: tert_mi2s_sleep {
				drive-strength = <2>;	/* 2 mA */
				bias-pull-down;		/* PULL DOWN */
			};
			tert_mi2s_active: tert_mi2s_active {
				drive-strength = <8>;	/* 8 mA */
				bias-disable;		/* NO PULL */
				output-high;
			};
		};

                pmx_tert_mi2s_mclk {
			qcom,pins = <&gp 73>;
			qcom,num-grp-pins = <1>;
			qcom,pin-func = <1>;
			label = "tert_mi2s_mclk";
			tert_mi2s_mclk_sleep: tert_mi2s_mclk_sleep {
				drive-strength = <2>;	/* 2 mA */
				bias-pull-down;		/* PULL DOWN */
			};
			tert_mi2s_mclk_active: tert_mi2s_mclk_active {
				drive-strength = <8>;	/* 8 mA */
				bias-disable;		/* NO PULL */
			};
		};

		pmx_tert_mi2s_sd0 {
			qcom,pins = <&gp 76>;
			qcom,num-grp-pins = <1>;
			qcom,pin-func = <1>;
			label = "tert_mi2s_sd0";
			tert_mi2s_sd0_sleep: tert_mi2s_sd0_sleep {
				drive-strength = <2>;	/* 2 mA */
				bias-pull-down;		/* PULL DOWN */
			};
			tert_mi2s_sd0_active: tert_mi2s_sd0_active {
				drive-strength = <8>;	/* 8 mA */
				bias-disable;		/* NO PULL */
			};
		};

		pmx_tert_mi2s_sd1 {
			qcom,pins = <&gp 77>;
			qcom,num-grp-pins = <1>;
			qcom,pin-func = <1>;
			label = "tert_mi2s_sd1";
			tert_mi2s_sd1_sleep: tert_mi2s_sd1_sleep {
				drive-strength = <2>;	/* 2 mA */
				bias-pull-down;		/* PULL DOWN */
			};
			tert_mi2s_sd1_active: tert_mi2s_sd1_active {
				drive-strength = <8>;	/* 8 mA */
				bias-disable;		/* NO PULL */
			};
		};

		pmx_quat_mi2s {
			qcom,pins = <&gp 58>, <&gp 59>;
			qcom,num-grp-pins = <2>;
			qcom,pin-func = <1>;
			label = "quat_mi2s";
			quat_mi2s_sleep: quat_mi2s_sleep {
				drive-strength = <2>;	/* 2 mA */
				bias-pull-down;		/* PULL DOWN */
			};
			quat_mi2s_active: quat_mi2s_active {
				drive-strength = <8>;	/* 8 mA */
				bias-disable;		/* NO PULL */
				output-high;
			};
		};

                pmx_quat_mi2s_mclk {
			qcom,pins = <&gp 57>;
			qcom,num-grp-pins = <1>;
			qcom,pin-func = <1>;
			label = "quat_mi2s_mclk";
			quat_mi2s_mclk_sleep: quat_mi2s_mclk_sleep {
				drive-strength = <2>;	/* 2 mA */
				bias-pull-down;		/* PULL DOWN */
			};
			quat_mi2s_mclk_active: quat_mi2s_mclk_active {
				drive-strength = <8>;	/* 8 mA */
				bias-disable;		/* NO PULL */
			};
		};

		pmx_quat_mi2s_sd0 {
			qcom,pins = <&gp 60>;
			qcom,num-grp-pins = <1>;
			qcom,pin-func = <1>;
			label = "quat_mi2s_sd0";
			quat_mi2s_sd0_sleep: quat_mi2s_sd0_sleep {
				drive-strength = <2>;	/* 2 mA */
				bias-pull-down;		/* PULL DOWN */
			};
			quat_mi2s_sd0_active: quat_mi2s_sd0_active {
				drive-strength = <8>;	/* 8 mA */
				bias-disable;		/* NO PULL */
			};
		};

		tsif0_signals {
			qcom,pins = <&gp 89>,	/* TSIF0 CLK */
				<&gp 90>,	/* TSIF0 Enable */
				<&gp 91>;	/* TSIF0 DATA */
			qcom,num-grp-pins = <3>;
			qcom,pin-func = <1>;
			label = "tsif0-signals";
			tsif0_signals_active: tsif0_signals_active {
				drive_strength = <2>;	/* 2 mA */
				bias-pull-down;		/* pull down */
			};
		};

		/* sync signal is only used if configured to mode-2 */
		tsif0_sync {
			qcom,pins = <&gp 110>;	/* TSIF0 SYNC */
			qcom,num-grp-pins = <1>;
			qcom,pin-func = <1>;
			label = "tsif0-sync";
			tsif0_sync_active: tsif0_sync_active {
				drive_strength = <2>;	/* 2 mA */
				bias-pull-down;		/* pull down */
			};
		};

		tsif1_signals {
			qcom,pins = <&gp 93>,	/* TSIF1 CLK */
				<&gp 94>,	/* TSIF1 Enable */
				<&gp 95>;	/* TSIF1 DATA */
			qcom,num-grp-pins = <3>;
			qcom,pin-func = <1>;
			label = "tsif1-signals";
			tsif1_signals_active: tsif1_signals_active {
				drive_strength = <2>;	/* 2 mA */
				bias-pull-down;		/* pull down */
			};
		};

		/* sync signal is only used if configured to mode-2 */
		tsif1_sync {
			qcom,pins = <&gp 96>;	/* TSIF1 SYNC */
			qcom,num-grp-pins = <1>;
			qcom,pin-func = <1>;
			label = "tsif1-sync";
			tsif1_sync_active: tsif1_sync_active {
				drive_strength = <2>;	/* 2 mA */
				bias-pull-down;		/* pull down */
			};
		};
	};
};
